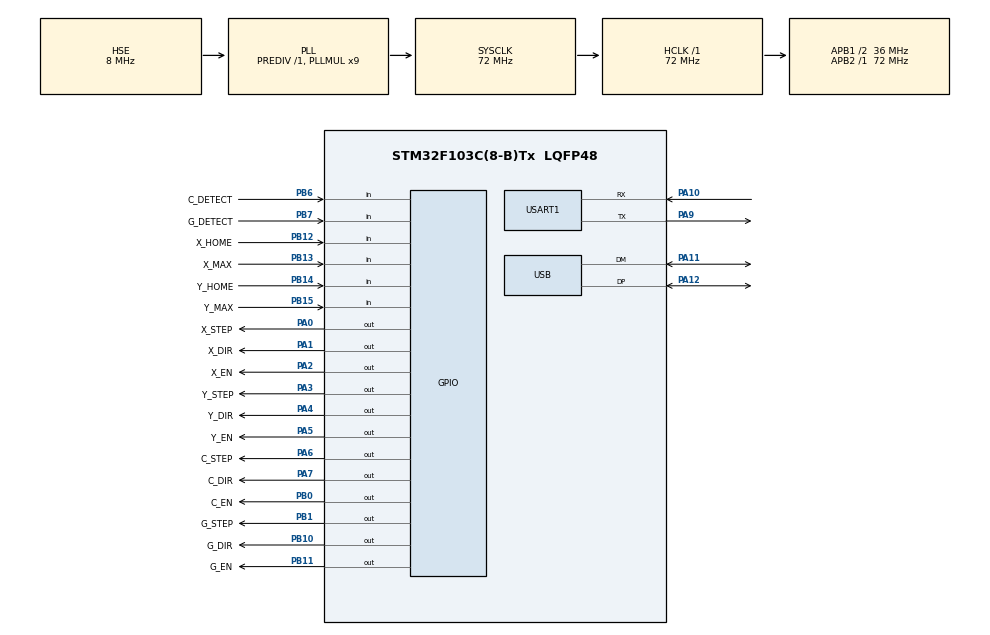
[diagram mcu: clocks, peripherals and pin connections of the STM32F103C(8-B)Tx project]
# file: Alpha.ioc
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FREERTOS.Queues01=motionQueue,10,uint8_t,0,Dynamic,NULL,NULL
FREERTOS.Tasks01=safetyTask,40,128,StartSafetyTask,Default,NULL,Dynamic,NULL,NULL;serialTask,24,256,StartSerialTask,Default,NULL,Dynamic,NULL,NULL;motionTask,32,256,StartMotionTask,Default,NULL,Dynamic,NULL,NULL;conveyorTask,24,256,StartConveyorTask,Default,NULL,Dynamic,NULL,NULL;gateTask,24,256,StartGateTask,Default,NULL,Dynamic,NULL,NULL
FREERTOS.configTOTAL_HEAP_SIZE=6144
IWDG.Prescaler=IWDG_PRESCALER_32
Mcu.Family=STM32F1
Mcu.Name=STM32F103C(8-B)Tx
Mcu.Package=LQFP48
NVIC.PriorityGroup=NVIC_PRIORITYGROUP_4
NVIC.TIM1_UP_IRQn=true\:15\:0\:false\:false\:true\:false\:false\:true\:true
NVIC.TimeBase=TIM1_UP_IRQn
NVIC.TimeBaseIP=TIM1
NVIC.USB_LP_CAN1_RX0_IRQn=true\:5\:0\:false\:false\:true\:true\:false\:true\:true
PA0-WKUP.GPIO_Label=X_STEP
PA0-WKUP.Signal=GPIO_Output
PA1.GPIO_Label=X_DIR
PA1.Signal=GPIO_Output
PA10.Mode=Asynchronous
PA10.Signal=USART1_RX
PA11.Mode=Device
PA11.Signal=USB_DM
PA12.Mode=Device
PA12.Signal=USB_DP
PA2.GPIO_Label=X_EN
PA2.Signal=GPIO_Output
PA3.GPIO_Label=Y_STEP
PA3.Signal=GPIO_Output
PA4.GPIO_Label=Y_DIR
PA4.Signal=GPIO_Output
PA5.GPIO_Label=Y_EN
PA5.Signal=GPIO_Output
PA6.GPIO_Label=C_STEP
PA6.Signal=GPIO_Output
PA7.GPIO_Label=C_DIR
PA7.Signal=GPIO_Output
PA9.Mode=Asynchronous
PA9.Signal=USART1_TX
PB0.GPIO_Label=C_EN
PB0.Signal=GPIO_Output
PB1.GPIO_Label=G_STEP
PB1.Signal=GPIO_Output
PB10.GPIO_Label=G_DIR
PB10.Signal=GPIO_Output
PB11.GPIO_Label=G_EN
PB11.Signal=GPIO_Output
PB12.GPIO_Label=X_HOME
PB12.GPIO_PuPd=GPIO_PULLUP
PB12.Signal=GPIO_Input
PB13.GPIO_Label=X_MAX
PB13.GPIO_PuPd=GPIO_PULLUP
PB13.Signal=GPIO_Input
PB14.GPIO_Label=Y_HOME
PB14.GPIO_PuPd=GPIO_PULLUP
PB14.Signal=GPIO_Input
PB15.GPIO_Label=Y_MAX
PB15.GPIO_PuPd=GPIO_PULLUP
PB15.Signal=GPIO_Input
PB6.GPIO_Label=C_DETECT
PB6.GPIO_PuPd=GPIO_PULLUP
PB6.Signal=GPIO_Input
PB7.GPIO_Label=G_DETECT
PB7.GPIO_PuPd=GPIO_PULLUP
PB7.Signal=GPIO_Input
PC14-OSC32_IN.Mode=LSE-External-Oscillator
PC14-OSC32_IN.Signal=RCC_OSC32_IN
PC15-OSC32_OUT.Mode=LSE-External-Oscillator
PC15-OSC32_OUT.Signal=RCC_OSC32_OUT
PD0-OSC_IN.Mode=HSE-External-Oscillator
PD0-OSC_IN.Signal=RCC_OSC_IN
PD1-OSC_OUT.Mode=HSE-External-Oscillator
PD1-OSC_OUT.Signal=RCC_OSC_OUT
ProjectManager.HeapSize=0x200
ProjectManager.StackSize=0x400
ProjectManager.TargetToolchain=CMake
RCC.AHBFreq_Value=72000000
RCC.APB1CLKDivider=RCC_HCLK_DIV2
RCC.APB1Freq_Value=36000000
RCC.APB1TimFreq_Value=72000000
RCC.APB2Freq_Value=72000000
RCC.APB2TimFreq_Value=72000000
RCC.HCLKFreq_Value=72000000
RCC.PLLMUL=RCC_PLL_MUL9
RCC.SYSCLKFreq_VALUE=72000000
RCC.SYSCLKSource=RCC_SYSCLKSOURCE_PLLCLK
RCC.USBFreq_Value=48000000
RCC.USBPrescaler=RCC_USBCLKSOURCE_PLL_DIV1_5
USART1.VirtualMode=VM_ASYNC
USB_DEVICE.CLASS_NAME_FS=DFU
USB_DEVICE.VirtualMode=Dfu
USB_DEVICE.VirtualModeFS=Dfu_FS
VP_FREERTOS_VS_CMSIS_V2.Mode=CMSIS_V2
VP_IWDG_VS_IWDG.Mode=IWDG_Activate
VP_SYS_VS_ND.Mode=No_Debug
VP_SYS_VS_tim1.Mode=TIM1
VP_USB_DEVICE_VS_USB_DEVICE_DFU_FS.Mode=DFU_FS
board=custom

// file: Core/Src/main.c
/* USER CODE BEGIN Header */
/**
  ******************************************************************************
  * @file           : main.c
  * @brief          : Main program body
  ******************************************************************************
  * @attention
  *
  * Copyright (c) 2026 STMicroelectronics.
  * All rights reserved.
  *
  * This software is licensed under terms that can be found in the LICENSE file
  * in the root directory of this software component.
  * If no LICENSE file comes with this software, it is provided AS-IS.
  *
  ******************************************************************************
  */
/* USER CODE END Header */
#include "main.h"
#include "cmsis_os.h"
#include "usb_device.h"

IWDG_HandleTypeDef hiwdg;

UART_HandleTypeDef huart1;

/* Definitions for safetyTask */
osThreadId_t safetyTaskHandle;
const osThreadAttr_t safetyTask_attributes = {
  .name = "safetyTask",
  .stack_size = 128 * 4,
  .priority = (osPriority_t) osPriorityHigh,
};
/* Definitions for serialTask */
osThreadId_t serialTaskHandle;
const osThreadAttr_t serialTask_attributes = {
  .name = "serialTask",
  .stack_size = 256 * 4,
  .priority = (osPriority_t) osPriorityNormal,
};
/* Definitions for motionTask */
osThreadId_t motionTaskHandle;
const osThreadAttr_t motionTask_attributes = {
  .name = "motionTask",
  .stack_size = 256 * 4,
  .priority = (osPriority_t) osPriorityAboveNormal,
};
/* Definitions for conveyorTask */
osThreadId_t conveyorTaskHandle;
const osThreadAttr_t conveyorTask_attributes = {
  .name = "conveyorTask",
  .stack_size = 256 * 4,
  .priority = (osPriority_t) osPriorityNormal,
};
/* Definitions for gateTask */
osThreadId_t gateTaskHandle;
const osThreadAttr_t gateTask_attributes = {
  .name = "gateTask",
  .stack_size = 256 * 4,
  .priority = (osPriority_t) osPriorityNormal,
};
/* Definitions for motionQueue */
osMessageQueueId_t motionQueueHandle;
const osMessageQueueAttr_t motionQueue_attributes = {
  .name = "motionQueue"
};

void SystemClock_Config(void);
static void MX_GPIO_Init(void);
static void MX_IWDG_Init(void);
static void MX_USART1_UART_Init(void);
void StartSafetyTask(void *argument);
void StartSerialTask(void *argument);
void StartMotionTask(void *argument);
void StartConveyorTask(void *argument);
void StartGateTask(void *argument);

int main(void)
{

  /* MCU Configuration--------------------------------------------------------*/

  /* Reset of all peripherals, Initializes the Flash interface and the Systick. */
  HAL_Init();

  /* Configure the system clock */
  SystemClock_Config();

  /* Initialize all configured peripherals */
  MX_GPIO_Init();
  MX_IWDG_Init();
  MX_USART1_UART_Init();

  /* Init scheduler */
  osKernelInitialize();

  /* Create the queue(s) */
  /* creation of motionQueue */
  motionQueueHandle = osMessageQueueNew (10, sizeof(uint8_t), &motionQueue_attributes);

  /* Create the thread(s) */
  /* creation of safetyTask */
  safetyTaskHandle = osThreadNew(StartSafetyTask, NULL, &safetyTask_attributes);

  /* creation of serialTask */
  serialTaskHandle = osThreadNew(StartSerialTask, NULL, &serialTask_attributes);

  /* creation of motionTask */
  motionTaskHandle = osThreadNew(StartMotionTask, NULL, &motionTask_attributes);

  /* creation of conveyorTask */
  conveyorTaskHandle = osThreadNew(StartConveyorTask, NULL, &conveyorTask_attributes);

  /* creation of gateTask */
  gateTaskHandle = osThreadNew(StartGateTask, NULL, &gateTask_attributes);

  /* Start scheduler */
  osKernelStart();

  /* We should never get here as control is now taken by the scheduler */

  /* Infinite loop */
  while (1)
  {

  }
}

void SystemClock_Config(void)
{
  RCC_OscInitTypeDef RCC_OscInitStruct = {0};
  RCC_ClkInitTypeDef RCC_ClkInitStruct = {0};
  RCC_PeriphCLKInitTypeDef PeriphClkInit = {0};

  /** Initializes the RCC Oscillators according to the specified parameters
  * in the RCC_OscInitTypeDef structure.
  */
  RCC_OscInitStruct.OscillatorType = RCC_OSCILLATORTYPE_LSI|RCC_OSCILLATORTYPE_HSE;
  RCC_OscInitStruct.HSEState = RCC_HSE_ON;
  RCC_OscInitStruct.HSEPredivValue = RCC_HSE_PREDIV_DIV1;
  RCC_OscInitStruct.HSIState = RCC_HSI_ON;
  RCC_OscInitStruct.LSIState = RCC_LSI_ON;
  RCC_OscInitStruct.PLL.PLLState = RCC_PLL_ON;
  RCC_OscInitStruct.PLL.PLLSource = RCC_PLLSOURCE_HSE;
  RCC_OscInitStruct.PLL.PLLMUL = RCC_PLL_MUL9;
  if (HAL_RCC_OscConfig(&RCC_OscInitStruct) != HAL_OK)
  {
    Error_Handler();
  }

  /** Initializes the CPU, AHB and APB buses clocks
  */
  RCC_ClkInitStruct.ClockType = RCC_CLOCKTYPE_HCLK|RCC_CLOCKTYPE_SYSCLK
                              |RCC_CLOCKTYPE_PCLK1|RCC_CLOCKTYPE_PCLK2;
  RCC_ClkInitStruct.SYSCLKSource = RCC_SYSCLKSOURCE_PLLCLK;
  RCC_ClkInitStruct.AHBCLKDivider = RCC_SYSCLK_DIV1;
  RCC_ClkInitStruct.APB1CLKDivider = RCC_HCLK_DIV2;
  RCC_ClkInitStruct.APB2CLKDivider = RCC_HCLK_DIV1;

  if (HAL_RCC_ClockConfig(&RCC_ClkInitStruct, FLASH_LATENCY_2) != HAL_OK)
  {
    Error_Handler();
  }
  PeriphClkInit.PeriphClockSelection = RCC_PERIPHCLK_USB;
  PeriphClkInit.UsbClockSelection = RCC_USBCLKSOURCE_PLL_DIV1_5;
  if (HAL_RCCEx_PeriphCLKConfig(&PeriphClkInit) != HAL_OK)
  {
    Error_Handler();
  }
}

static void MX_IWDG_Init(void)
{

  hiwdg.Instance = IWDG;
  hiwdg.Init.Prescaler = IWDG_PRESCALER_32;
  hiwdg.Init.Reload = 4095;
  if (HAL_IWDG_Init(&hiwdg) != HAL_OK)
  {
    Error_Handler();
  }

}

static void MX_USART1_UART_Init(void)
{

  huart1.Instance = USART1;
  huart1.Init.BaudRate = 115200;
  huart1.Init.WordLength = UART_WORDLENGTH_8B;
  huart1.Init.StopBits = UART_STOPBITS_1;
  huart1.Init.Parity = UART_PARITY_NONE;
  huart1.Init.Mode = UART_MODE_TX_RX;
  huart1.Init.HwFlowCtl = UART_HWCONTROL_NONE;
  huart1.Init.OverSampling = UART_OVERSAMPLING_16;
  if (HAL_UART_Init(&huart1) != HAL_OK)
  {
    Error_Handler();
  }

}

static void MX_GPIO_Init(void)
{
  GPIO_InitTypeDef GPIO_InitStruct = {0};

  /* GPIO Ports Clock Enable */
  __HAL_RCC_GPIOC_CLK_ENABLE();
  __HAL_RCC_GPIOD_CLK_ENABLE();
  __HAL_RCC_GPIOA_CLK_ENABLE();
  __HAL_RCC_GPIOB_CLK_ENABLE();

  /*Configure GPIO pin Output Level */
  HAL_GPIO_WritePin(GPIOA, X_STEP_Pin|X_DIR_Pin|X_EN_Pin|Y_STEP_Pin
                          |Y_DIR_Pin|Y_EN_Pin|C_STEP_Pin|C_DIR_Pin, GPIO_PIN_RESET);

  /*Configure GPIO pin Output Level */
  HAL_GPIO_WritePin(GPIOB, C_EN_Pin|G_STEP_Pin|G_DIR_Pin|G_EN_Pin, GPIO_PIN_RESET);

  /*Configure GPIO pins : X_STEP_Pin X_DIR_Pin X_EN_Pin Y_STEP_Pin
                           Y_DIR_Pin Y_EN_Pin C_STEP_Pin C_DIR_Pin */
  GPIO_InitStruct.Pin = X_STEP_Pin|X_DIR_Pin|X_EN_Pin|Y_STEP_Pin
                          |Y_DIR_Pin|Y_EN_Pin|C_STEP_Pin|C_DIR_Pin;
  GPIO_InitStruct.Mode = GPIO_MODE_OUTPUT_PP;
  GPIO_InitStruct.Pull = GPIO_NOPULL;
  GPIO_InitStruct.Speed = GPIO_SPEED_FREQ_LOW;
  HAL_GPIO_Init(GPIOA, &GPIO_InitStruct);

  /*Configure GPIO pins : C_EN_Pin G_STEP_Pin G_DIR_Pin G_EN_Pin */
  GPIO_InitStruct.Pin = C_EN_Pin|G_STEP_Pin|G_DIR_Pin|G_EN_Pin;
  GPIO_InitStruct.Mode = GPIO_MODE_OUTPUT_PP;
  GPIO_InitStruct.Pull = GPIO_NOPULL;
  GPIO_InitStruct.Speed = GPIO_SPEED_FREQ_LOW;
  HAL_GPIO_Init(GPIOB, &GPIO_InitStruct);

  /*Configure GPIO pins : X_HOME_Pin X_MAX_Pin Y_HOME_Pin Y_MAX_Pin
                           C_DETECT_Pin G_DETECT_Pin */
  GPIO_InitStruct.Pin = X_HOME_Pin|X_MAX_Pin|Y_HOME_Pin|Y_MAX_Pin
                          |C_DETECT_Pin|G_DETECT_Pin;
  GPIO_InitStruct.Mode = GPIO_MODE_INPUT;
  GPIO_InitStruct.Pull = GPIO_PULLUP;
  HAL_GPIO_Init(GPIOB, &GPIO_InitStruct);

}

void StartSafetyTask(void *argument)
{
  /* init code for USB_DEVICE */
  MX_USB_DEVICE_Init();
  for(;;)
  {
    osDelay(1);
  }
}

void StartSerialTask(void *argument)
{
  for(;;)
  {
    osDelay(1);
  }
}

void StartMotionTask(void *argument)
{
  for(;;)
  {
    osDelay(1);
  }
}

void StartConveyorTask(void *argument)
{
  for(;;)
  {
    osDelay(1);
  }
}

void StartGateTask(void *argument)
{
  for(;;)
  {
    osDelay(1);
  }
}

void HAL_TIM_PeriodElapsedCallback(TIM_HandleTypeDef *htim)
{
  if (htim->Instance == TIM1)
  {
    HAL_IncTick();
  }
}

void Error_Handler(void)
{
  __disable_irq();
  while (1)
  {
  }
}

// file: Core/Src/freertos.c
/* USER CODE BEGIN Header */
/**
  ******************************************************************************
  * File Name          : freertos.c
  * Description        : Code for freertos applications
  ******************************************************************************
  * @attention
  *
  * Copyright (c) 2026 STMicroelectronics.
  * All rights reserved.
  *
  * This software is licensed under terms that can be found in the LICENSE file
  * in the root directory of this software component.
  * If no LICENSE file comes with this software, it is provided AS-IS.
  *
  ******************************************************************************
  */
/* USER CODE END Header */

#include "FreeRTOS.h"
#include "task.h"
#include "main.h"

/* USER CODE BEGIN Includes */
#include <stdbool.h>
typedef struct {
  int32_t target_x;
  int32_t target_y;
  uint8_t command_type;
} MotionCommand_t;
/* USER CODE END Includes */

/* USER CODE BEGIN Variables */
extern osMessageQueueId_t motionQueueHandle;
/* USER CODE END Variables */
